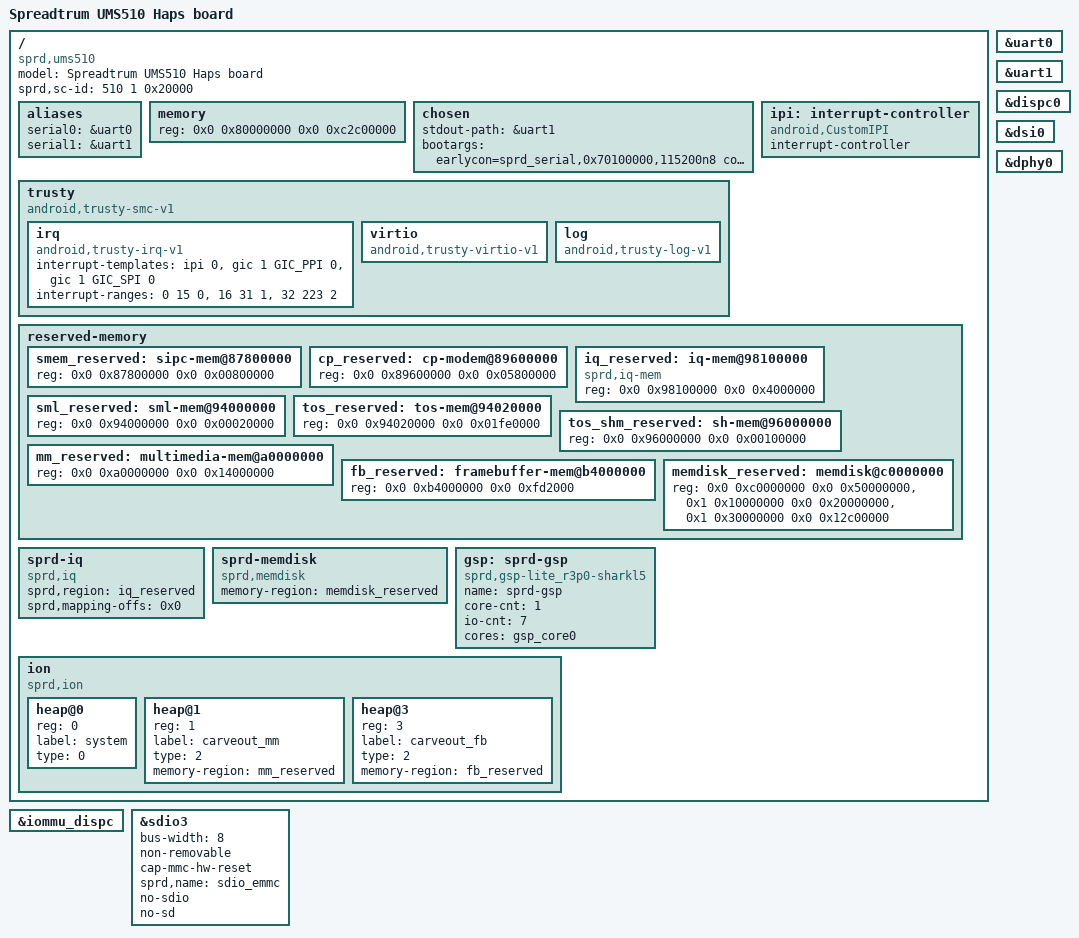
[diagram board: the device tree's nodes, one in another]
// SPDX-License-Identifier: (GPL-2.0+ OR MIT)
/*
 * Spreadtrum Sharkl5 platform DTS file
 *
 * Copyright (C) 2018, Spreadtrum Communications Inc.
 */

/dts-v1/;

#include "ums510.dtsi"

/ {
	model = "Spreadtrum UMS510 Haps board";

	compatible = "sprd,ums510";

	sprd,sc-id = <510 1 0x20000>;

	aliases {
		serial0 = &uart0;
		serial1 = &uart1;
	};

	memory {
		device_type = "memory";
		reg = <0x0 0x80000000 0x0 0xc2c00000>;
	};

	chosen {
		stdout-path = &uart1;
		bootargs = "earlycon=sprd_serial,0x70100000,115200n8 console=ttyS1,115200n8 loglevel=11 maxcpus=1 init=/init root=/dev/ram0 rw androidboot.hardware=ums510_haps androidboot.selinux=permissive";
	};

	ipi: interrupt-controller {
		compatible = "android,CustomIPI";
		#interrupt-cells = <1>;
		interrupt-controller;
	};

	trusty {
		compatible = "android,trusty-smc-v1";
		irq {
			compatible = "android,trusty-irq-v1";
			interrupt-templates = <&ipi 0>,
				<&gic 1 GIC_PPI 0>,
				<&gic 1 GIC_SPI 0>;
			interrupt-ranges = < 0  15 0>,
					<16  31 1>,
					<32 223 2>;
		};

		virtio {
			compatible = "android,trusty-virtio-v1";
		};

		log {
			compatible = "android,trusty-log-v1";
		};
	};

	reserved-memory {
		#address-cells = <2>;
		#size-cells = <2>;
		ranges;

		smem_reserved: sipc-mem@87800000{
			reg = <0x0 0x87800000 0x0 0x00800000>;
		};

		cp_reserved: cp-modem@89600000 {
			reg = <0x0 0x89600000 0x0 0x05800000>;
		};

		/* Only used for iq, will be removed in normal mode by uboot */
		iq_reserved: iq-mem@98100000{
			compatible = "sprd,iq-mem";
			reg = <0x0 0x98100000 0x0 0x4000000>;
		};

		/* must be 64M aligned */
		sml_reserved: sml-mem@94000000{
			reg = <0x0 0x94000000 0x0 0x00020000>;
		};

		tos_reserved: tos-mem@94020000{
			reg = <0x0 0x94020000 0x0 0x01fe0000>;
		};

		tos_shm_reserved: sh-mem@96000000{
			reg = <0x0 0x96000000 0x0 0x00100000>;
		};

		mm_reserved: multimedia-mem@a0000000{
			reg = <0x0 0xa0000000 0x0 0x14000000>;
		};

		fb_reserved: framebuffer-mem@b4000000{
			reg = <0x0 0xb4000000 0x0 0xfd2000>;
		};

		memdisk_reserved: memdisk@c0000000{
			reg = <0x0 0xc0000000 0x0 0x50000000>,  /* system 1280M */
				<0x1 0x10000000 0x0 0x20000000>, /* userdata 512M */
				<0x1 0x30000000 0x0 0x12c00000>; /* vendor 300M */
		};
	};

	sprd-iq {
		compatible = "sprd,iq";
		sprd,region = <&iq_reserved>;
		sprd,mapping-offs = <0x0>;
	};

	sprd-memdisk {
		compatible = "sprd,memdisk";
		memory-region = <&memdisk_reserved>;
	};

	gsp: sprd-gsp {
		compatible = "sprd,gsp-lite_r3p0-sharkl5";
		name = "sprd-gsp";
		core-cnt = <1>;
		io-cnt = <7>;
		cores = <&gsp_core0>;
	};

	ion {
		compatible = "sprd,ion";
		#address-cells = <1>;
		#size-cells = <0>;

		heap@0 {
			reg = <0>;
			label = "system";
			type = <0>;
		};


		heap@1 {
			reg = <1>;
			label = "carveout_mm";
			type = <2>;
			memory-region = <&mm_reserved>;
		};

		heap@3 {
			reg = <3>;
			label = "carveout_fb";
			type = <2>;
			memory-region = <&fb_reserved>;
		};
	};
};

&uart0 {
	status = "okay";
};

&uart1 {
	status = "okay";
};

&dispc0 {
	status = "okay";
};

&iommu_dispc {
	status = "okay";
};

&dsi0 {
	status = "okay";
};

&dphy0 {
	status = "okay";
};

&sdio3 {
	bus-width = <8>;
	non-removable;
	cap-mmc-hw-reset;
	sprd,name = "sdio_emmc";
	no-sdio;
	no-sd;
	status = "okay";
};
